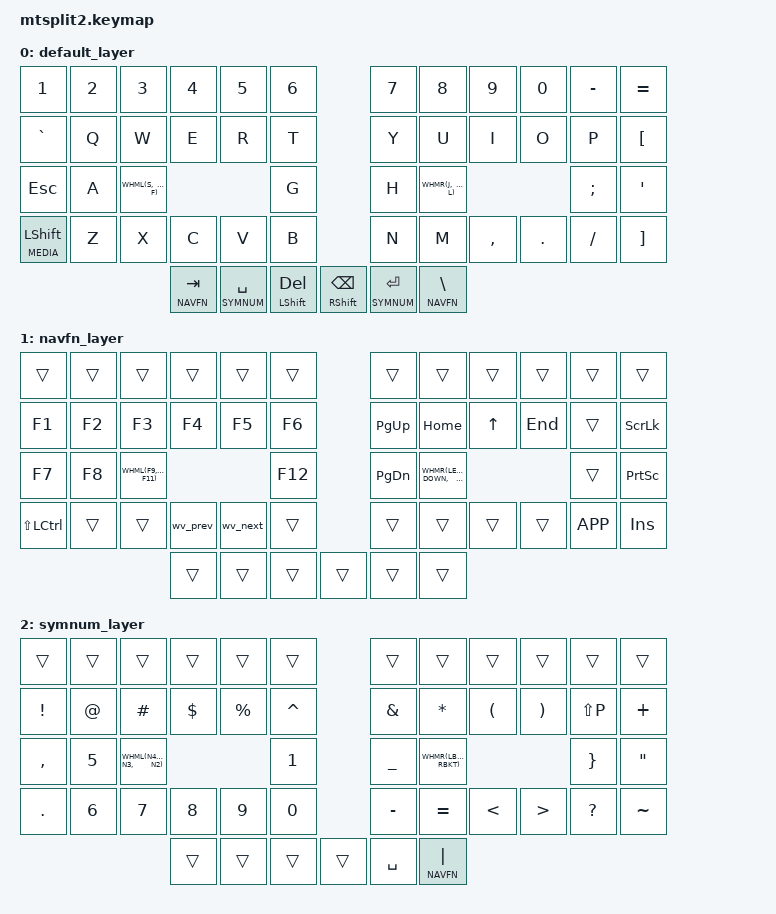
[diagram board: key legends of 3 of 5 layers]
/*
 * Copyright (c) 2020 The ZMK Contributors
 *
 * SPDX-License-Identifier: MIT
 */

#include <behaviors.dtsi>
#include <dt-bindings/zmk/keys.h>
#include <dt-bindings/zmk/bt.h>
#include <dt-bindings/zmk/outputs.h>

#define DEFAULT     0
#define NAVFN       1
#define SYMNUM      2
#define MEDIA       3
#define ADJUST      4

#define WHML(s, d ,f) &hml LGUI s   &hml LALT d     &hml LCTRL f
#define WHMR(j, k, l) &hmr RCTRL j  &hmr LALT k     &hmr RCMD l

#define MHML(s, d, f) &hml LCTRL s  &hml LALT d     &hml LGUI f
#define MHMR(j, k, l) &hmr RCMD j   &hmr LALT k     &hmr RCTRL l

#define WCOMBO(name, keys, code) name { \
    timeout-ms = <20>; \
    key-positions = <keys>; \
    bindings = <&kp code>; \
    require-prior-idle-ms = <125>; \
    layers = <0 1 2>; \
};


&lt {
    flavor = "hold-preferred";
};

&mt {
    quick-tap-ms = <200>;
};

&sk {
    lazy;
    quick-release;
};


/ {
        behaviors {
            hml: homerow_mods_left {
                compatible = "zmk,behavior-hold-tap";
                label = "LEFT_HOMEROW_MODS";
                #binding-cells = <2>;
                tapping-term-ms = <150>;
                quick-tap-ms = <125>;
                require-prior-idle-ms = <125>;
                flavor = "balanced";
                bindings = <&kp>, <&kp>;
                hold-trigger-key-positions = <6 7 8 9 10 11     18 19 20 21 22 23   30 31 32 33 34 35   42 43 44 45 46 47   48 49 50 51 52 53>;
            };
            hmr: homerow_mods_right {
                compatible = "zmk,behavior-hold-tap";
                label = "RIGHT_HOMEROW_MODS";
                #binding-cells = <2>;
                tapping-term-ms = <150>;
                quick-tap-ms = <125>;
                require-prior-idle-ms = <125>;
                flavor = "balanced";
                bindings = <&kp>, <&kp>;
                hold-trigger-key-positions = <0 1 2 3 4 5   12 13 14 15 16 17   24 25 26 27 28 29   36 37 38 39 40 41   48 49 50 51 52 53>;
            };
            th: thumb_hold_tap {
                compatible = "zmk,behavior-hold-tap";
                label = "THUMB_LAYER_TAPS";
                #binding-cells = <2>;
                tapping-term-ms = <200>;
                quick-tap-ms = <200>;
                flavor = "hold-preferred";
                bindings = <&mo>, <&kp>;
            };
            skh: sticky_hold {
                compatible = "zmk,behavior-hold-tap";
                #binding-cells = <2>;
                tapping-term-ms = <200>;
                bindings = <&mo>, <&sk>;
            };
        };

        conditional_layers {
            compatible = "zmk,conditional-layers";
            tri_layer {
                if-layers = <NAVFN SYMNUM>;
                then-layer = <ADJUST>;
            };
        };

        macros {
            ZMK_MACRO(wv_next, bindings = <&macro_press &kp LCTL &kp LGUI>, <&macro_tap &kp RIGHT>, <&macro_release &kp LCTL &kp LGUI>;)
            ZMK_MACRO(wv_prev, bindings = <&macro_press &kp LCTL &kp LGUI>, <&macro_tap &kp LEFT>, <&macro_release &kp LCTL &kp LGUI>;)
            ZMK_MACRO(mv_next, bindings = <&macro_press &kp LGUI>, <&macro_tap &kp RIGHT>, <&macro_release &kp LGUI>;)
            ZMK_MACRO(mv_prev, bindings = <&macro_press &kp LGUI>, <&macro_tap &kp LEFT>, <&macro_release &kp LGUI>;)
        };

        combos {
            compatible = "zmk,combos";
            
            WCOMBO(lctlalt, 27 28, LC(LALT))
            WCOMBO(rctlalt, 31 32, LC(LALT))
            WCOMBO(lctlwin, 26 28, LC(LWIN))
            WCOMBO(rctlwin, 31 33, LC(LWIN))
            WCOMBO(laltwin, 26 27, LG(LALT))
            WCOMBO(raltwin, 32 33, LG(LALT))
            WCOMBO(lhyper, 26 27 28, LC(LG(LALT)))
            WCOMBO(rhyper, 31 32 33, LC(LG(LALT)))
        };

        keymap {
                compatible = "zmk,keymap";

// -----------------------------------------------------------------------------------------
                default_layer {
                    bindings = <
            &kp  N1           &kp N2    &kp N3      &kp N4          &kp N5           &kp N6                              &kp N7          &kp N8      &kp N9      &kp N0  &kp MINUS   &kp EQUAL
            &kp  GRAVE        &kp Q     &kp W       &kp E           &kp R            &kp T                               &kp Y           &kp U       &kp I       &kp O   &kp P       &kp LBKT
            &kp  ESC          &kp A     WHML(S,     D,              F)               &kp G                               &kp H           WHMR(J,     K,          L)      &kp SEMI    &kp SQT
            &skh MEDIA LSHFT  &kp Z     &kp X       &kp C           &kp V            &kp B                               &kp N           &kp M       &kp COMMA   &kp DOT &kp FSLH    &kp RBKT
                                                    &th NAVFN TAB   &lt SYMNUM SPACE &mt LSHFT DEL       &mt RSHFT BSPC  &lt SYMNUM RET  &th NAVFN BSLH    
                        >;
                };

// -----------------------------------------------------------------------------------------
                navfn_layer {
                    bindings = <     
            &trans       &trans    &trans    &trans      &trans      &trans                                           &trans      &trans     &trans   &trans      &trans     &trans
            &kp F1       &kp F2    &kp F3    &kp F4      &kp F5      &kp F6                                           &kp PG_UP   &kp HOME   &kp UP   &kp END     &trans     &kp SLCK 
            &kp F7       &kp F8    WHML(F9,  F10,        F11)        &kp F12                                          &kp PG_DN   WHMR(LEFT, DOWN,    RIGHT)      &trans     &kp PSCRN
            &kp LS(LCTL) &trans    &trans    &wv_prev    &wv_next    &trans                                           &trans      &trans     &trans   &trans      &kp K_APP  &kp INS
                                                         &trans      &trans      &trans                     &trans    &trans      &trans
                        >;
                };

// -----------------------------------------------------------------------------------------
                symnum_layer {
                    bindings = <
            &trans      &trans    &trans        &trans      &trans      &trans                            &trans        &trans      &trans      &trans      &trans      &trans
            &kp EXCL    &kp AT    &kp HASH      &kp DLLR    &kp PRCNT   &kp CARET                         &kp AMPS      &kp STAR    &kp LPAR    &kp RPAR    &kp LS(P)   &kp PLUS 
            &kp COMMA   &kp N5    WHML(N4,      N3,         N2)         &kp N1                            &kp UNDER     WHMR(LBRC,  LBKT,       RBKT)       &kp RBRC    &kp DQT
            &kp DOT     &kp N6    &kp N7        &kp N8      &kp N9      &kp N0                            &kp MINUS     &kp EQUAL   &kp LT      &kp GT      &kp QMARK   &kp TILDE
                                                            &trans      &trans      &trans      &trans    &kp SPACE     &th NAVFN PIPE
                        >;
                };

// -----------------------------------------------------------------------------------------
                media_layer {
                    bindings = <
            &trans          &trans          &trans        &trans      &trans      &trans                            &trans      &kp KP_EQUAL &kp KP_SLASH   &kp KP_ASTERISK &kp KP_MINUS    &trans
            &trans          &kp C_CAPTIONS  &kp C_RW      &trans      &kp C_FF    &trans                            &trans      &kp KP_N7    &kp KP_N8      &kp KP_N9       &kp KP_PLUS     &kp KP_NLCK
            &kp CAPS        &trans          &kp C_PREV    &kp C_PP    &kp C_NEXT  &kp C_VOL_UP                      &trans      &kp KP_N4    &kp KP_N5      &kp KP_N6       &kp KP_PLUS     &trans
            &trans          &trans          &trans        &trans      &kp C_MUTE  &kp C_VOL_DN                      &trans      &kp KP_N1    &kp KP_N2      &kp KP_N3       &kp KP_DOT      &trans
                                                                      &trans      &trans      &trans      &trans    &trans      &kp KP_N0
                        >;
                };


// -----------------------------------------------------------------------------------------
                adjust_layer {
                    bindings = <
        &trans          &trans         &trans          &trans          &trans          &trans                               &trans          &trans          &trans          &trans          &trans          &trans
        &sys_reset      &bootloader    &trans          &trans          &trans          &trans                               &trans          &trans          &trans          &trans          &bootloader     &sys_reset
        &bt BT_CLR      &bt BT_SEL 0   &bt BT_SEL 1    &bt BT_SEL 2    &bt BT_SEL 3    &bt BT_SEL 4                         &bt BT_SEL 4    &bt BT_SEL 3    &bt BT_SEL 2    &bt BT_SEL 1    &bt BT_SEL 0    &bt BT_CLR
        &out OUT_BLE    &out OUT_USB   &trans          &trans          &trans          &trans                               &trans          &trans          &trans          &trans          &out OUT_USB    &out OUT_BLE
                                                                       &trans          &trans       &trans      &trans      &trans          &trans          
                        >;
                };
        };
};
